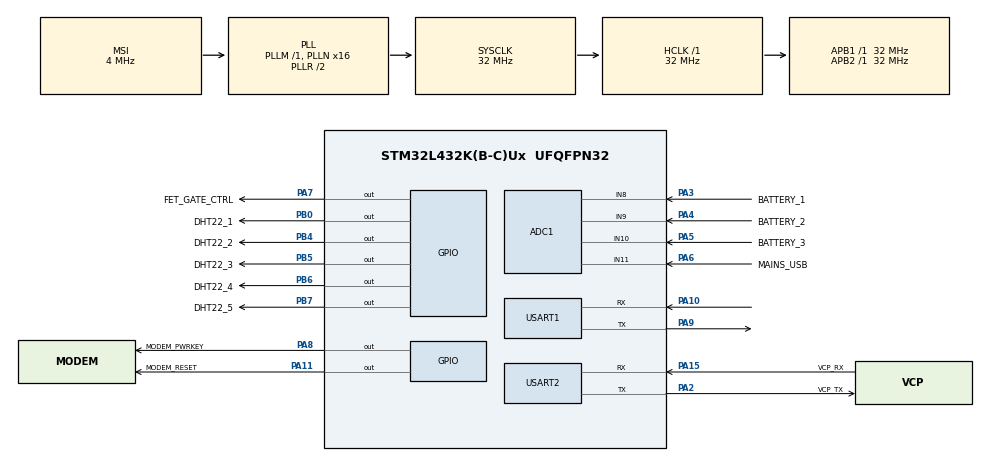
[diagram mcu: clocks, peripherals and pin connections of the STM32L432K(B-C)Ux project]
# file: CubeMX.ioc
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ADC1.Channel-0\#ChannelRegularConversion=ADC_CHANNEL_8
ADC1.Channel-1\#ChannelRegularConversion=ADC_CHANNEL_9
ADC1.Channel-2\#ChannelRegularConversion=ADC_CHANNEL_10
ADC1.Channel-3\#ChannelRegularConversion=ADC_CHANNEL_11
ADC1.NbrOfConversion=4
ADC1.NbrOfConversionFlag=1
ADC1.OffsetNumber-0\#ChannelRegularConversion=ADC_OFFSET_NONE
ADC1.OffsetNumber-1\#ChannelRegularConversion=ADC_OFFSET_NONE
ADC1.OffsetNumber-2\#ChannelRegularConversion=ADC_OFFSET_NONE
ADC1.OffsetNumber-3\#ChannelRegularConversion=ADC_OFFSET_NONE
ADC1.Rank-0\#ChannelRegularConversion=1
ADC1.Rank-1\#ChannelRegularConversion=2
ADC1.Rank-2\#ChannelRegularConversion=3
ADC1.Rank-3\#ChannelRegularConversion=4
ADC1.SamplingTime-0\#ChannelRegularConversion=ADC_SAMPLETIME_92CYCLES_5
ADC1.SamplingTime-1\#ChannelRegularConversion=ADC_SAMPLETIME_92CYCLES_5
ADC1.SamplingTime-2\#ChannelRegularConversion=ADC_SAMPLETIME_92CYCLES_5
ADC1.SamplingTime-3\#ChannelRegularConversion=ADC_SAMPLETIME_92CYCLES_5
ADC1.master=1
Dma.ADC1.3.Direction=DMA_PERIPH_TO_MEMORY
Dma.ADC1.3.Instance=DMA1_Channel1
Dma.ADC1.3.MemDataAlignment=DMA_MDATAALIGN_HALFWORD
Dma.ADC1.3.MemInc=DMA_MINC_ENABLE
Dma.ADC1.3.Mode=DMA_NORMAL
Dma.ADC1.3.PeriphDataAlignment=DMA_PDATAALIGN_HALFWORD
Dma.ADC1.3.PeriphInc=DMA_PINC_DISABLE
Dma.ADC1.3.Priority=DMA_PRIORITY_LOW
Dma.Request0=USART1_RX
Dma.Request1=USART1_TX
Dma.Request2=USART2_RX
Dma.Request3=ADC1
Dma.USART1_RX.0.Direction=DMA_PERIPH_TO_MEMORY
Dma.USART1_RX.0.Instance=DMA1_Channel5
Dma.USART1_RX.0.MemDataAlignment=DMA_MDATAALIGN_BYTE
Dma.USART1_RX.0.MemInc=DMA_MINC_ENABLE
Dma.USART1_RX.0.Mode=DMA_CIRCULAR
Dma.USART1_RX.0.PeriphDataAlignment=DMA_PDATAALIGN_BYTE
Dma.USART1_RX.0.PeriphInc=DMA_PINC_DISABLE
Dma.USART1_RX.0.Priority=DMA_PRIORITY_LOW
Dma.USART1_TX.1.Direction=DMA_MEMORY_TO_PERIPH
Dma.USART1_TX.1.Instance=DMA1_Channel4
Dma.USART1_TX.1.MemDataAlignment=DMA_MDATAALIGN_BYTE
Dma.USART1_TX.1.MemInc=DMA_MINC_ENABLE
Dma.USART1_TX.1.Mode=DMA_NORMAL
Dma.USART1_TX.1.PeriphDataAlignment=DMA_PDATAALIGN_BYTE
Dma.USART1_TX.1.PeriphInc=DMA_PINC_DISABLE
Dma.USART1_TX.1.Priority=DMA_PRIORITY_LOW
Dma.USART2_RX.2.Direction=DMA_PERIPH_TO_MEMORY
Dma.USART2_RX.2.Instance=DMA1_Channel6
Dma.USART2_RX.2.MemDataAlignment=DMA_MDATAALIGN_BYTE
Dma.USART2_RX.2.MemInc=DMA_MINC_ENABLE
Dma.USART2_RX.2.Mode=DMA_CIRCULAR
Dma.USART2_RX.2.PeriphDataAlignment=DMA_PDATAALIGN_BYTE
Dma.USART2_RX.2.PeriphInc=DMA_PINC_DISABLE
Dma.USART2_RX.2.Priority=DMA_PRIORITY_LOW
IWDG.Prescaler=IWDG_PRESCALER_256
Mcu.Family=STM32L4
Mcu.Name=STM32L432K(B-C)Ux
Mcu.Package=UFQFPN32
NVIC.DMA1_Channel1_IRQn=true\:0\:0\:false\:false\:true\:false\:true\:true
NVIC.DMA1_Channel4_IRQn=true\:0\:0\:false\:false\:true\:false\:true\:true
NVIC.DMA1_Channel5_IRQn=true\:0\:0\:false\:false\:true\:false\:true\:true
NVIC.DMA1_Channel6_IRQn=true\:0\:0\:false\:false\:true\:false\:true\:true
NVIC.PriorityGroup=NVIC_PRIORITYGROUP_4
NVIC.RTC_WKUP_IRQn=true\:0\:0\:false\:false\:true\:true\:true\:true
NVIC.USART1_IRQn=true\:0\:0\:false\:false\:true\:true\:true\:true
NVIC.USART2_IRQn=true\:0\:0\:false\:false\:true\:true\:true\:true
PA0.GPIO_Label=MCO [High speed clock in]
PA0.Signal=RCC_CK_IN
PA10.Mode=Asynchronous
PA10.Signal=USART1_RX
PA11.GPIO_Label=MODEM_RESET
PA11.GPIO_ModeDefaultOutputPP=GPIO_MODE_OUTPUT_OD
PA11.GPIO_PuPd=GPIO_PULLUP
PA11.PinState=GPIO_PIN_SET
PA11.Signal=GPIO_Output
PA13\ (JTMS-SWDIO).GPIO_Label=SWDIO
PA13\ (JTMS-SWDIO).Mode=Serial_Wire
PA13\ (JTMS-SWDIO).Signal=SYS_JTMS-SWDIO
PA14\ (JTCK-SWCLK).GPIO_Label=SWCLK
PA14\ (JTCK-SWCLK).Mode=Serial_Wire
PA14\ (JTCK-SWCLK).Signal=SYS_JTCK-SWCLK
PA15\ (JTDI).GPIO_Label=VCP_RX
PA15\ (JTDI).Mode=Asynchronous
PA15\ (JTDI).Signal=USART2_RX
PA2.GPIO_Label=VCP_TX
PA2.Mode=Asynchronous
PA2.Signal=USART2_TX
PA3.GPIO_Label=BATTERY_1
PA3.Signal=ADCx_IN8
PA4.GPIO_Label=BATTERY_2
PA4.Signal=ADCx_IN9
PA5.GPIO_Label=BATTERY_3
PA5.Signal=ADCx_IN10
PA6.GPIO_Label=MAINS_USB
PA6.Signal=ADCx_IN11
PA7.GPIO_Label=FET_GATE_CTRL
PA7.Signal=GPIO_Output
PA8.GPIO_Label=MODEM_PWRKEY
PA8.GPIO_ModeDefaultOutputPP=GPIO_MODE_OUTPUT_OD
PA8.GPIO_PuPd=GPIO_PULLUP
PA8.PinState=GPIO_PIN_SET
PA8.Signal=GPIO_Output
PA9.Mode=Asynchronous
PA9.Signal=USART1_TX
PB0.GPIO_Label=DHT22_1
PB0.GPIO_ModeDefaultOutputPP=GPIO_MODE_OUTPUT_OD
PB0.GPIO_PuPd=GPIO_NOPULL
PB0.GPIO_Speed=GPIO_SPEED_FREQ_HIGH
PB0.PinState=GPIO_PIN_SET
PB0.Signal=GPIO_Output
PB4\ (NJTRST).GPIO_Label=DHT22_2
PB4\ (NJTRST).GPIO_ModeDefaultOutputPP=GPIO_MODE_OUTPUT_OD
PB4\ (NJTRST).GPIO_PuPd=GPIO_NOPULL
PB4\ (NJTRST).GPIO_Speed=GPIO_SPEED_FREQ_HIGH
PB4\ (NJTRST).PinState=GPIO_PIN_SET
PB4\ (NJTRST).Signal=GPIO_Output
PB5.GPIO_Label=DHT22_3
PB5.GPIO_ModeDefaultOutputPP=GPIO_MODE_OUTPUT_OD
PB5.GPIO_PuPd=GPIO_NOPULL
PB5.GPIO_Speed=GPIO_SPEED_FREQ_HIGH
PB5.PinState=GPIO_PIN_SET
PB5.Signal=GPIO_Output
PB6.GPIO_FM6=__NULL
PB6.GPIO_Label=DHT22_4
PB6.GPIO_ModeDefaultOutputPP=GPIO_MODE_OUTPUT_OD
PB6.GPIO_PuPd=GPIO_NOPULL
PB6.GPIO_Speed=GPIO_SPEED_FREQ_HIGH
PB6.PinState=GPIO_PIN_SET
PB6.Signal=GPIO_Output
PB7.GPIO_Label=DHT22_5
PB7.GPIO_ModeDefaultOutputPP=GPIO_MODE_OUTPUT_OD
PB7.GPIO_PuPd=GPIO_NOPULL
PB7.GPIO_Speed=GPIO_SPEED_FREQ_HIGH
PB7.PinState=GPIO_PIN_SET
PB7.Signal=GPIO_Output
PC14-OSC32_IN\ (PC14).Mode=LSE-External-Oscillator
PC14-OSC32_IN\ (PC14).Signal=RCC_OSC32_IN
PC15-OSC32_OUT\ (PC15).Mode=LSE-External-Oscillator
PC15-OSC32_OUT\ (PC15).Signal=RCC_OSC32_OUT
ProjectManager.HeapSize=0x200
ProjectManager.StackSize=0x400
ProjectManager.TargetToolchain=Makefile
RCC.ADCFreq_Value=32000000
RCC.AHBFreq_Value=32000000
RCC.APB1Freq_Value=32000000
RCC.APB1TimFreq_Value=32000000
RCC.APB2Freq_Value=32000000
RCC.APB2TimFreq_Value=32000000
RCC.CortexFreq_Value=32000000
RCC.HCLKFreq_Value=32000000
RCC.HSE_VALUE=8000000
RCC.HSI16_VALUE=16000000
RCC.HSI48_VALUE=48000000
RCC.HSI_VALUE=16000000
RCC.MSI_VALUE=4000000
RCC.PLLMUL=RCC_PLLMUL_4
RCC.PLLN=16
RCC.PLLSAI1N=16
RCC.SYSCLKFreq_VALUE=32000000
RCC.SYSCLKSource=RCC_SYSCLKSOURCE_PLLCLK
RCC.USBFreq_Value=32000000
RCC.VCOOutputFreq_Value=64000000
SH.ADCx_IN10.0=ADC1_IN10,IN10-Single-Ended
SH.ADCx_IN11.0=ADC1_IN11,IN11-Single-Ended
SH.ADCx_IN8.0=ADC1_IN8,IN8-Single-Ended
SH.ADCx_IN9.0=ADC1_IN9,IN9-Single-Ended
TIM2.Prescaler=31
TIM6.AutoReloadPreload=TIM_AUTORELOAD_PRELOAD_ENABLE
TIM6.Prescaler=79
USART1.VirtualMode-Asynchronous=VM_ASYNC
USART2.VirtualMode-Asynchronous=VM_ASYNC
VP_IWDG_VS_IWDG.Mode=IWDG_Activate
VP_RCC_LSE.Mode=CRS SYNC Source LSE
VP_RTC_VS_RTC_Activate.Mode=RTC_Enabled
VP_RTC_VS_RTC_Calendar.Mode=RTC_Calendar
VP_RTC_VS_RTC_WakeUp_intern.Mode=WakeUp
VP_TIM2_VS_ClockSourceINT.Mode=Internal
VP_TIM6_VS_ClockSourceINT.Mode=Enable_Timer
board=NUCLEO-L432KC

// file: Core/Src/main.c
/* USER CODE BEGIN Header */
/**
  ******************************************************************************
  * @file           : main.c
  * @brief          : Main program body
  ******************************************************************************
  * @attention
  *
  * Copyright (c) 2026 STMicroelectronics.
  * All rights reserved.
  *
  * This software is licensed under terms that can be found in the LICENSE file
  * in the root directory of this software component.
  * If no LICENSE file comes with this software, it is provided AS-IS.
  *
  ******************************************************************************
  */
/* USER CODE END Header */
#include "main.h"
#include "adc.h"
#include "dma.h"
#include "iwdg.h"
#include "rtc.h"
#include "tim.h"
#include "usart.h"
#include "gpio.h"

/* USER CODE BEGIN Includes */
#include "app.h"
/* USER CODE END Includes */

void SystemClock_Config(void);

int main(void)
{

  /* MCU Configuration--------------------------------------------------------*/

  /* Reset of all peripherals, Initializes the Flash interface and the Systick. */
  HAL_Init();

  /* Configure the system clock */
  SystemClock_Config();

  /* Initialize all configured peripherals */
  MX_GPIO_Init();
  MX_DMA_Init();
  MX_ADC1_Init();
  MX_IWDG_Init();
  MX_RTC_Init();
  MX_TIM6_Init();
  MX_USART1_UART_Init();
  MX_USART2_UART_Init();
  MX_TIM2_Init();
  /* USER CODE BEGIN 2 */
  // call the main application code
  App ();
  /* USER CODE END 2 */

  /* Infinite loop */

}

void SystemClock_Config(void)
{
  RCC_OscInitTypeDef RCC_OscInitStruct = {0};
  RCC_ClkInitTypeDef RCC_ClkInitStruct = {0};
  RCC_CRSInitTypeDef RCC_CRSInitStruct = {0};

  /** Configure the main internal regulator output voltage
  */
  if (HAL_PWREx_ControlVoltageScaling(PWR_REGULATOR_VOLTAGE_SCALE1) != HAL_OK)
  {
    Error_Handler();
  }

  /** Configure LSE Drive Capability
  */
  HAL_PWR_EnableBkUpAccess();
  __HAL_RCC_LSEDRIVE_CONFIG(RCC_LSEDRIVE_LOW);

  /** Initializes the RCC Oscillators according to the specified parameters
  * in the RCC_OscInitTypeDef structure.
  */
  RCC_OscInitStruct.OscillatorType = RCC_OSCILLATORTYPE_LSI|RCC_OSCILLATORTYPE_LSE
                              |RCC_OSCILLATORTYPE_MSI;
  RCC_OscInitStruct.LSEState = RCC_LSE_ON;
  RCC_OscInitStruct.LSIState = RCC_LSI_ON;
  RCC_OscInitStruct.MSIState = RCC_MSI_ON;
  RCC_OscInitStruct.MSICalibrationValue = 0;
  RCC_OscInitStruct.MSIClockRange = RCC_MSIRANGE_6;
  RCC_OscInitStruct.PLL.PLLState = RCC_PLL_ON;
  RCC_OscInitStruct.PLL.PLLSource = RCC_PLLSOURCE_MSI;
  RCC_OscInitStruct.PLL.PLLM = 1;
  RCC_OscInitStruct.PLL.PLLN = 16;
  RCC_OscInitStruct.PLL.PLLP = RCC_PLLP_DIV7;
  RCC_OscInitStruct.PLL.PLLQ = RCC_PLLQ_DIV2;
  RCC_OscInitStruct.PLL.PLLR = RCC_PLLR_DIV2;
  if (HAL_RCC_OscConfig(&RCC_OscInitStruct) != HAL_OK)
  {
    Error_Handler();
  }

  /** Initializes the CPU, AHB and APB buses clocks
  */
  RCC_ClkInitStruct.ClockType = RCC_CLOCKTYPE_HCLK|RCC_CLOCKTYPE_SYSCLK
                              |RCC_CLOCKTYPE_PCLK1|RCC_CLOCKTYPE_PCLK2;
  RCC_ClkInitStruct.SYSCLKSource = RCC_SYSCLKSOURCE_PLLCLK;
  RCC_ClkInitStruct.AHBCLKDivider = RCC_SYSCLK_DIV1;
  RCC_ClkInitStruct.APB1CLKDivider = RCC_HCLK_DIV1;
  RCC_ClkInitStruct.APB2CLKDivider = RCC_HCLK_DIV1;

  if (HAL_RCC_ClockConfig(&RCC_ClkInitStruct, FLASH_LATENCY_1) != HAL_OK)
  {
    Error_Handler();
  }

  /** Enable MSI Auto calibration
  */
  HAL_RCCEx_EnableMSIPLLMode();

  /** Enable the SYSCFG APB clock
  */
  __HAL_RCC_CRS_CLK_ENABLE();

  /** Configures CRS
  */
  RCC_CRSInitStruct.Prescaler = RCC_CRS_SYNC_DIV1;
  RCC_CRSInitStruct.Source = RCC_CRS_SYNC_SOURCE_LSE;
  RCC_CRSInitStruct.Polarity = RCC_CRS_SYNC_POLARITY_RISING;
  RCC_CRSInitStruct.ReloadValue = __HAL_RCC_CRS_RELOADVALUE_CALCULATE(48000000,32768);
  RCC_CRSInitStruct.ErrorLimitValue = 34;
  RCC_CRSInitStruct.HSI48CalibrationValue = 32;

  HAL_RCCEx_CRSConfig(&RCC_CRSInitStruct);
}

void Error_Handler(void)
{
  /* USER CODE BEGIN Error_Handler_Debug */
  /* User can add his own implementation to report the HAL error return state */
  __disable_irq();
  AppError ();
  /* USER CODE END Error_Handler_Debug */
}
